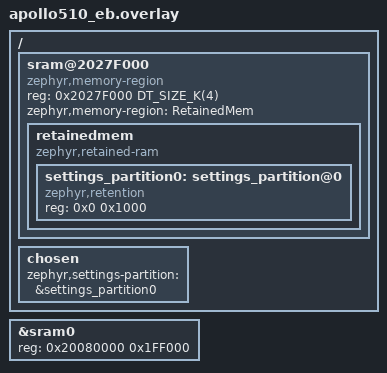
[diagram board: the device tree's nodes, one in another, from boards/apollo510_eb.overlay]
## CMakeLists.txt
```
# SPDX-License-Identifier: Apache-2.0

cmake_minimum_required(VERSION 3.28.0)
find_package(Zephyr REQUIRED HINTS $ENV{ZEPHYR_BASE})
project(settings_retention)

add_subdirectory(./src zms_test_bindir)
```

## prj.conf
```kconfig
CONFIG_ZTEST=y
CONFIG_RETAINED_MEM=y
CONFIG_RETENTION=y

CONFIG_SETTINGS=y
CONFIG_SETTINGS_RUNTIME=y
CONFIG_SETTINGS_RETENTION=y
```

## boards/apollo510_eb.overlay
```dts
/ {
	sram@2027F000 {
		compatible = "zephyr,memory-region", "mmio-sram";
		reg = <0x2027F000 DT_SIZE_K(4)>;
		zephyr,memory-region = "RetainedMem";
		status = "okay";

		retainedmem {
			compatible = "zephyr,retained-ram";
			status = "okay";
			#address-cells = <1>;
			#size-cells = <1>;

			settings_partition0: settings_partition@0 {
				compatible = "zephyr,retention";
				status = "okay";
				reg = <0x0 0x1000>;
			};
		};
	};

	chosen {
		zephyr,settings-partition = &settings_partition0;
	};
};

&sram0 {
	reg = <0x20080000 0x1FF000>;
};
```

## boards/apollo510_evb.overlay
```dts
/ {
	sram@201FF000 {
		compatible = "zephyr,memory-region", "mmio-sram";
		reg = <0x201FF000 DT_SIZE_K(4)>;
		zephyr,memory-region = "RetainedMem";
		status = "okay";

		retainedmem {
			compatible = "zephyr,retained-ram";
			status = "okay";
			#address-cells = <1>;
			#size-cells = <1>;

			settings_partition0: settings_partition@0 {
				compatible = "zephyr,retention";
				status = "okay";
				reg = <0x0 0x1000>;
			};
		};
	};

	chosen {
		zephyr,settings-partition = &settings_partition0;
	};
};

&sram0 {
	reg = <SSRAM_BASE_ADDR 0x17F000>;
};
```

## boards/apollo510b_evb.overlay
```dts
/*****************************************************************************
 * SPDX-FileCopyrightText: 2025 Ambiq Micro Inc.
 *
 * SPDX-License-Identifier: Apache-2.0
 ***************************************************************************
 */

/ {
	sram@2027F000 {
		compatible = "zephyr,memory-region", "mmio-sram";
		reg = <0x2027F000 DT_SIZE_K(4)>;
		zephyr,memory-region = "RetainedMem";
		status = "okay";

		retainedmem {
			compatible = "zephyr,retained-ram";
			status = "okay";
			#address-cells = <1>;
			#size-cells = <1>;

			settings_partition0: settings_partition@0 {
				compatible = "zephyr,retention";
				status = "okay";
				reg = <0x0 0x1000>;
			};
		};
	};

	chosen {
		zephyr,settings-partition = &settings_partition0;
	};
};

&sram0 {
	reg = <0x20080000 0x1FF000>;
};
```

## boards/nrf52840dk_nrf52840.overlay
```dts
/*
 * Copyright (c) 2025 Nordic Semiconductor ASA
 *
 * SPDX-License-Identifier: Apache-2.0
 */

/ {
	chosen {
		/delete-property/ zephyr,boot-mode;
	};

	chosen {
		zephyr,settings-partition = &settings_partition0;
	};

	sram@2003f000 {
		compatible = "zephyr,memory-region", "mmio-sram";
		reg = <0x2003f000 DT_SIZE_K(4)>;
		ranges = <0x0 0x2003f000 DT_SIZE_K(4)>;
		#address-cells = <1>;
		#size-cells = <1>;
		zephyr,memory-region = "RetainedMem";
		status = "okay";

		retainedmem {
			compatible = "zephyr,retained-ram";
			ranges;
			#address-cells = <1>;
			#size-cells = <1>;
			status = "okay";

			settings_partition0: settings_partition@0 {
				compatible = "zephyr,retention";
				reg = <0x0 0x1000>;
				status = "okay";
			};
		};
	};
};

&sram0 {
	reg = <0x20000000 DT_SIZE_K(252)>;
};
```

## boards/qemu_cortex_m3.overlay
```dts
/*
 * Copyright (c) 2025 Nordic Semiconductor ASA
 *
 * SPDX-License-Identifier: Apache-2.0
 */

/ {
	chosen {
		zephyr,settings-partition = &settings_partition0;
	};

	sram@2000f000 {
		compatible = "zephyr,memory-region", "mmio-sram";
		reg = <0x2000f000 0x1000>;
		ranges = <0x0 0x2000f000 0x1000>;
		#address-cells = <1>;
		#size-cells = <1>;
		zephyr,memory-region = "RetainedMem";
		status = "okay";

		retainedmem {
			compatible = "zephyr,retained-ram";
			ranges;
			#address-cells = <1>;
			#size-cells = <1>;
			status = "okay";

			settings_partition0: settings_partition@0 {
				compatible = "zephyr,retention";
				reg = <0x0 0x1000>;
				status = "okay";
			};
		};
	};
};

&sram0 {
	reg = <0x20000000 0xf000>;
};
```

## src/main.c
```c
/*
 * Copyright (c) 2024 BayLibre SAS
 *
 * SPDX-License-Identifier: Apache-2.0
 */
#include <stdlib.h>
#include <string.h>

#include <settings_priv.h>
#include "settings_test.h"

uint8_t val8;
uint8_t val8_un;
uint32_t val32;
uint64_t val64;

int test_get_called;
int test_set_called;
int test_commit_called;
int test_export_block;

int c1_handle_get(const char *name, char *val, int val_len_max);
int c1_handle_set(const char *name, size_t len, settings_read_cb read_cb, void *cb_arg);
int c1_handle_commit(void);
int c1_handle_export(int (*cb)(const char *name, const void *value, size_t val_len));

struct settings_handler c_test_handlers[] = {
	{.name = "myfoo",
	 .h_get = c1_handle_get,
	 .h_set = c1_handle_set,
	 .h_commit = c1_handle_commit,
	 .h_export = c1_handle_export},
};

int c1_handle_get(const char *name, char *val, int val_len_max)
{
	const char *next;

	if (val_len_max < 0) {
		return -EINVAL;
	}

	test_get_called = 1;

	if (settings_name_steq(name, "mybar", &next) && !next) {
		val_len_max = MIN(val_len_max, sizeof(val8));
		memcpy(val, &val8, MIN(val_len_max, sizeof(val8)));
		return val_len_max;
	}

	if (settings_name_steq(name, "mybar64", &next) && !next) {
		val_len_max = MIN(val_len_max, sizeof(val64));
		memcpy(val, &val64, MIN(val_len_max, sizeof(val64)));
		return val_len_max;
	}

	return -ENOENT;
}

int c1_handle_set(const char *name, size_t len, settings_read_cb read_cb, void *cb_arg)
{
	size_t val_len;
	int rc;
	const char *next;

	test_set_called = 1;
	if (settings_name_steq(name, "mybar", &next) && !next) {
		rc = read_cb(cb_arg, &val8, sizeof(val8));
		zassert_true(rc >= 0, "SETTINGS_VALUE_SET callback");
		return 0;
	}

	if (settings_name_steq(name, "mybar64", &next) && !next) {
		rc = read_cb(cb_arg, &val64, sizeof(val64));
		zassert_true(rc >= 0, "SETTINGS_VALUE_SET callback");
		return 0;
	}

	if (settings_name_steq(name, "unaligned", &next) && !next) {
		val_len = len;
		zassert_equal(val_len, sizeof(val8_un), "value length: %zd, ought equal 1",
			      val_len);
		rc = read_cb(cb_arg, &val8_un, sizeof(val8_un));
		zassert_true(rc >= 0, "SETTINGS_VALUE_SET callback");
		return 0;
	}

	return -ENOENT;
}

int c1_handle_commit(void)
{
	test_commit_called = 1;
	return 0;
}

int c1_handle_export(int (*cb)(const char *name, const void *value, size_t val_len))
{
	if (test_export_block) {
		return 0;
	}

	(void)cb("myfoo/mybar", &val8, sizeof(val8));

	(void)cb("myfoo/mybar64", &val64, sizeof(val64));

	(void)cb("myfoo/unaligned", &val8_un, sizeof(val8_un));

	return 0;
}

void ctest_clear_call_state(void)
{
	test_get_called = 0;
	test_set_called = 0;
	test_commit_called = 0;
}

int ctest_get_call_state(void)
{
	return test_get_called + test_set_called + test_commit_called;
}

void config_wipe_srcs(void)
{
	sys_slist_init(&settings_load_srcs);
	settings_save_dst = NULL;
}

ZTEST_SUITE(settings_config, NULL, settings_config_setup, NULL, NULL, settings_config_teardown);
```

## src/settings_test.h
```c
/*
 * Copyright (c) 2024 BayLibre SAS
 *
 * SPDX-License-Identifier: Apache-2.0
 */

#ifndef _SETTINGS_TEST_H
#define _SETTINGS_TEST_H

#include <stdio.h>
#include <string.h>
#include <zephyr/ztest.h>

#include <zephyr/settings/settings.h>

#ifdef __cplusplus
extern "C" {
#endif

extern uint8_t val8;
extern uint8_t val8_un;
extern uint32_t val32;
extern uint64_t val64;

extern int test_get_called;
extern int test_set_called;
extern int test_commit_called;
extern int test_export_block;

extern struct settings_handler c_test_handlers[];

void ctest_clear_call_state(void);
int ctest_get_call_state(void);

void config_wipe_srcs(void);
void *settings_config_setup(void);
void settings_config_teardown(void *fixture);

#ifdef __cplusplus
}
#endif
#endif /* _SETTINGS_TEST_H */
```
